VERSION ""

NS_ :

BS_:

BU_: XXX

BO_ 1680 NEW_MSG_1: 8 XXX
 SG_ NEW_SIGNAL_1 : 55|8@0+ (1,0) [0|255] "" XXX
 SG_ Lights status : 39|4@0+ (1,0) [0|15] "" XXX

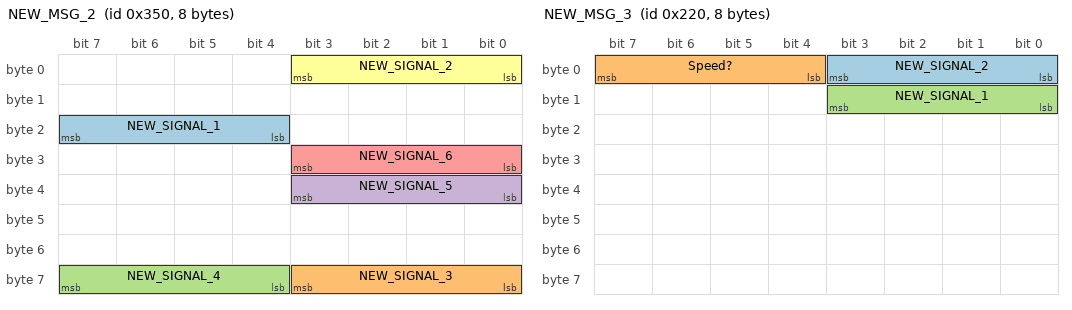
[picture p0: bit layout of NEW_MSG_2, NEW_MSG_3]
BO_ 848 NEW_MSG_2: 8 XXX
 SG_ NEW_SIGNAL_1 : 23|4@0+ (1,0) [0|15] "" XXX
 SG_ NEW_SIGNAL_3 : 56|4@1+ (1,0) [0|15] "" XXX
 SG_ NEW_SIGNAL_4 : 63|4@0+ (1,0) [0|15] "" XXX
 SG_ NEW_SIGNAL_5 : 35|4@0+ (1,0) [0|15] "" XXX
 SG_ NEW_SIGNAL_6 : 24|4@1+ (1,0) [0|15] "" XXX
 SG_ NEW_SIGNAL_2 : 0|4@1+ (1,0) [0|15] "" XXX

BO_ 544 NEW_MSG_3: 8 XXX
 SG_ NEW_SIGNAL_2 : 0|4@1+ (1,0) [0|15] "" XXX
 SG_ Speed? : 7|4@0+ (1,0) [0|15] "" XXX
 SG_ NEW_SIGNAL_1 : 8|4@1+ (1,0) [0|15] "" XXX
 SG_ High when stop? : 15|1@0+ (1,0) [0|3] "" XXX

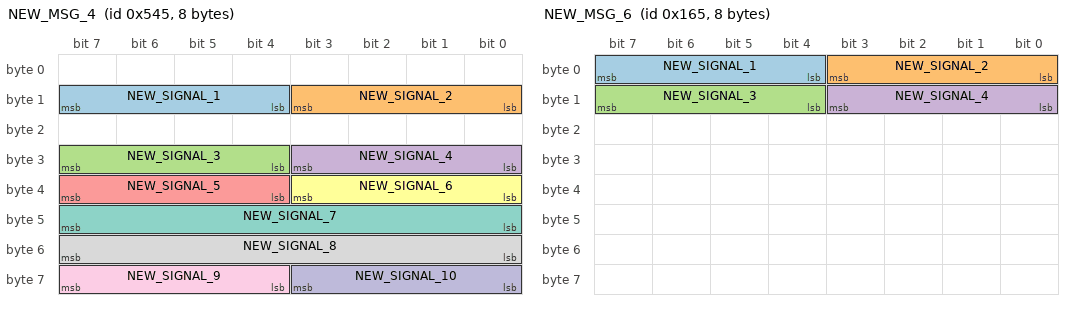
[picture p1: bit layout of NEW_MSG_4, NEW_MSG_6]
BO_ 1349 NEW_MSG_4: 8 XXX
 SG_ NEW_SIGNAL_1 : 15|4@0+ (1,0) [0|15] "" XXX
 SG_ NEW_SIGNAL_2 : 8|4@1+ (1,0) [0|15] "" XXX
 SG_ NEW_SIGNAL_3 : 31|4@0+ (1,0) [0|255] "" XXX
 SG_ NEW_SIGNAL_4 : 24|4@1+ (1,0) [0|15] "" XXX
 SG_ NEW_SIGNAL_5 : 39|4@0+ (1,0) [0|15] "" XXX
 SG_ NEW_SIGNAL_6 : 32|4@1+ (1,0) [0|15] "" XXX
 SG_ NEW_SIGNAL_7 : 40|8@1+ (1,0) [0|255] "" XXX
 SG_ NEW_SIGNAL_8 : 48|8@1+ (1,0) [0|255] "" XXX
 SG_ NEW_SIGNAL_9 : 60|4@1+ (1,0) [0|255] "" XXX
 SG_ NEW_SIGNAL_10 : 56|4@1+ (1,0) [0|15] "" XXX

BO_ 356 NEW_MSG_5: 8 XXX
 SG_ NEW_SIGNAL_1 : 48|8@1+ (1,0) [0|15] "" XXX
 SG_ NEW_SIGNAL_2 : 56|8@1+ (1,0) [0|15] "" XXX

BO_ 357 NEW_MSG_6: 8 XXX
 SG_ NEW_SIGNAL_1 : 7|4@0+ (1,0) [0|15] "" XXX
 SG_ NEW_SIGNAL_2 : 0|4@1+ (1,0) [0|15] "" XXX
 SG_ NEW_SIGNAL_3 : 15|4@0+ (1,0) [0|15] "" XXX
 SG_ NEW_SIGNAL_4 : 8|4@1+ (1,0) [0|15] "" XXX

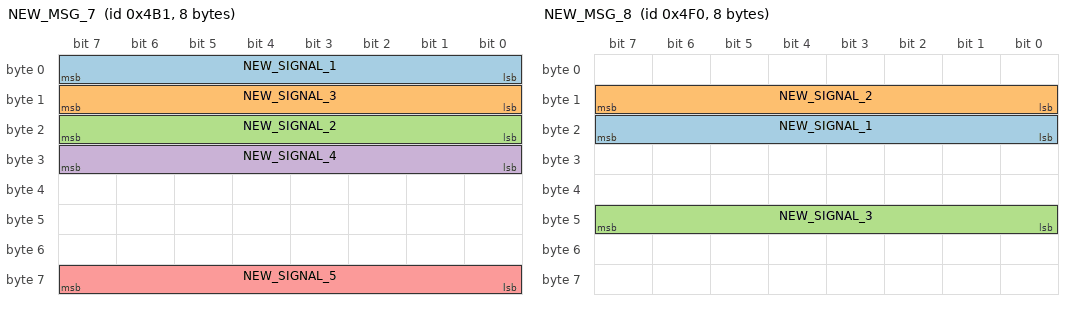
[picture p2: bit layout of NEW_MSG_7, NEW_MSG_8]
BO_ 1201 NEW_MSG_7: 8 XXX
 SG_ NEW_SIGNAL_1 : 7|8@0+ (1,0) [0|15] "" XXX
 SG_ NEW_SIGNAL_3 : 15|8@0+ (1,0) [0|255] "" XXX
 SG_ NEW_SIGNAL_2 : 16|8@1+ (1,0) [0|255] "" XXX
 SG_ NEW_SIGNAL_4 : 24|8@1+ (1,0) [0|255] "" XXX
 SG_ NEW_SIGNAL_5 : 56|8@1+ (1,0) [0|255] "" XXX

BO_ 1264 NEW_MSG_8: 8 XXX
 SG_ NEW_SIGNAL_1 : 23|8@0+ (1,0) [0|255] "" XXX
 SG_ NEW_SIGNAL_2 : 8|8@1+ (1,0) [0|15] "" XXX
 SG_ NEW_SIGNAL_3 : 40|8@1+ (1,0) [0|63] "" XXX

BO_ 704 No changes so far: 8 XXX

BO_ 1508 Same here: 8 XXX

BO_ 1520 No changes: 8 XXX

BO_ 1440 No changes: 8 XXX

BO_ 1442 No changes, though not null: 8 XXX

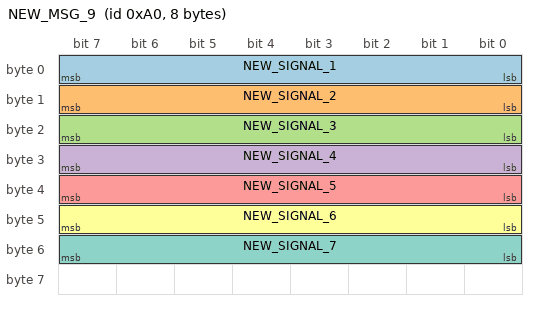
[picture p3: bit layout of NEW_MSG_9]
BO_ 160 NEW_MSG_9: 8 XXX
 SG_ NEW_SIGNAL_1 : 7|8@0+ (1,0) [0|255] "" XXX
 SG_ NEW_SIGNAL_2 : 8|8@1+ (1,0) [0|255] "" XXX
 SG_ NEW_SIGNAL_3 : 16|8@1+ (1,0) [0|255] "" XXX
 SG_ NEW_SIGNAL_4 : 24|8@1+ (1,0) [0|255] "" XXX
 SG_ NEW_SIGNAL_5 : 32|8@1+ (1,0) [0|255] "" XXX
 SG_ NEW_SIGNAL_6 : 40|8@1+ (1,0) [0|255] "" XXX
 SG_ NEW_SIGNAL_7 : 48|8@1+ (1,0) [0|255] "" XXX

BO_ 339 NEW_MSG_10: 8 XXX
 SG_ NEW_SIGNAL_1 : 55|8@0+ (1,0) [0|15] "" XXX
 SG_ NEW_SIGNAL_2 : 56|8@1+ (1,0) [0|255] "" XXX

BO_ 399 NEW_MSG_11: 8 XXX
 SG_ NEW_SIGNAL_1 : 40|8@1+ (1,0) [0|255] "" XXX
 SG_ NEW_SIGNAL_2 : 48|8@1+ (1,0) [0|255] "" XXX

BO_ 608 NEW_MSG_12: 8 XXX
 SG_ NEW_SIGNAL_1 : 8|8@1+ (1,0) [0|255] "" XXX
 SG_ NEW_SIGNAL_2 : 16|8@1+ (1,0) [0|255] "" XXX
